# STM32MP153 register map
File version: 1.3
CPU: CM4 r0p1, little endian, no MPU, FPU, 4 interrupt priority bits
Registers are 32-bit, read-write, reset 0x0 unless marked. A register's access mark holds for its fields unless they carry their own. Offsets are from the block's base; [hi:lo] are bit positions.

## ADC_common — Analog-to-Digital Converter
Base 0x48003300
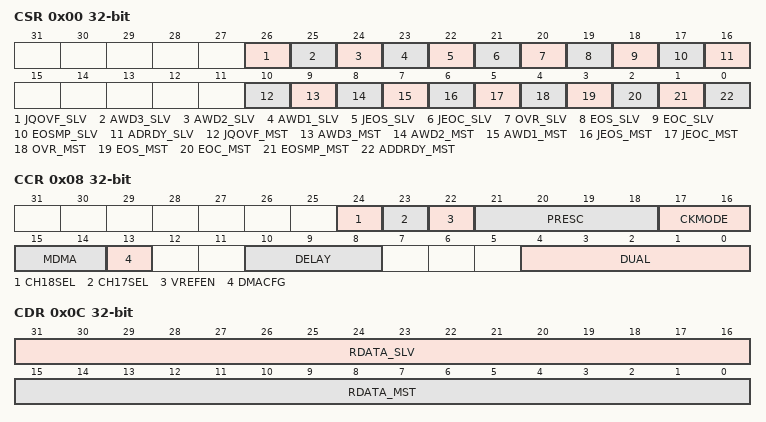
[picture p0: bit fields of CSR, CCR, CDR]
0x00 CSR ro — ADC Common status register
  [26] JQOVF_SLV, [25] AWD3_SLV, [24] AWD2_SLV, [23] AWD1_SLV, [22] JEOS_SLV, [21] JEOC_SLV, [20] OVR_SLV, [19] EOS_SLV, [18] EOC_SLV, [17] EOSMP_SLV, [16] ADRDY_SLV, [10] JQOVF_MST, [9] AWD3_MST, [8] AWD2_MST, [7] AWD1_MST, [6] JEOS_MST, [5] JEOC_MST, [4] OVR_MST, [3] EOS_MST, [2] EOC_MST, [1] EOSMP_MST, [0] ADDRDY_MST
0x08 CCR — ADC common control register
  [24] CH18SEL
  [23] CH17SEL
  [22] VREFEN — VREFINT enable
  [21:18] PRESC — ADC prescaler
  [17:16] CKMODE — ADC clock mode
  [15:14] MDMA
  [13] DMACFG
  [10:8] DELAY
  [4:0] DUAL
0x0C CDR ro — Common regular data register for dual mode
  [31:16] RDATA_SLV, [15:0] RDATA_MST
0x10 CDR2 ro — Common regular data register for dual mode
  [31:0] RDATA_ALT

## CCU
Base 0x44010000
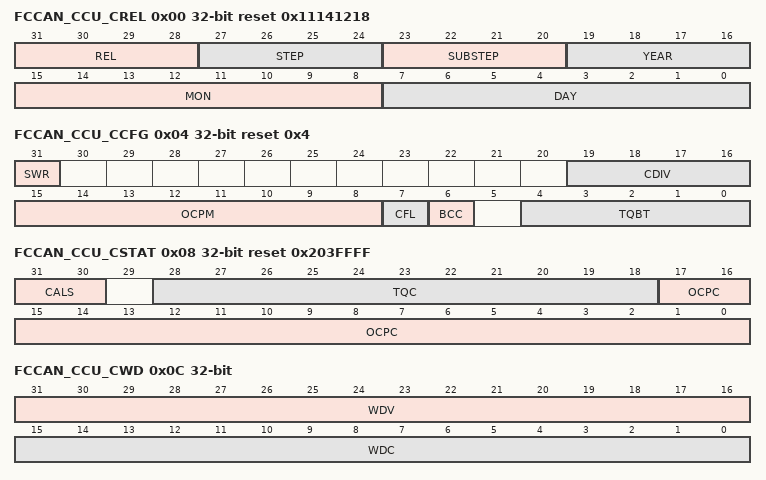
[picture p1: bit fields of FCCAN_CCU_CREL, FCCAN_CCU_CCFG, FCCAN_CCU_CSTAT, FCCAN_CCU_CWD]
0x00 FCCAN_CCU_CREL ro reset 0x11141218 — Clock calibration unit core release register
  [31:28] REL, [27:24] STEP, [23:20] SUBSTEP, [19:16] YEAR, [15:8] MON, [7:0] DAY
0x04 FCCAN_CCU_CCFG reset 0x4 — Calibration configuration register
  [31] SWR, [19:16] CDIV, [15:8] OCPM, [7] CFL, [6] BCC, [4:0] TQBT
0x08 FCCAN_CCU_CSTAT ro reset 0x203FFFF — Calibration status register
  [31:30] CALS, [28:18] TQC, [17:0] OCPC
0x0C FCCAN_CCU_CWD access per field — The calibration watchdog is started after the first falling edge when the calibration FSM is in state Not_Calibrated (CCU_CSTAT.CALS = 00). In this state the calibration watchdog monitors the message received. In case no message was received until the calibration watchdog has counted down to 0, the calibration FSM stays in state Not_Calibrated (CCU_CSTAT.CALS = 00), the counter is reloaded with FDCAN_RWD.WDC and basic calibration is restarted after the next falling edge. When in state Basic_Calibrated (CCU_CSTAT.CALS = 01), the calibration watchdog is restarted with each received message . In case no message was received until the calibration watchdog has counted down to 0, the calibration FSM returns to state Not_Calibrated (CCU_CSTAT.CALS = 00), the counter is reloaded with FDCAN_RWD.WDC and basic calibration is restarted after the next falling edge. When a quartz message is received, state Precision_Calibrated (CCU_CSTAT.CALS = 10) is entered and the calibration watchdog is restarted. In this state the calibration watchdog monitors the quartz message received input. In case no message from a quartz controlled node is received by the attached TTCAN until the calibration watchdog has counted down to 0, the calibration FSM transits back to state Basic_Calibrated (CCU_CSTAT.CALS = 01). The signal is active when the CAN protocol engine on the attached TTCAN is started i.e. when the INIT bit is reset. A calibration watchdog event also sets interrupt flag CCU_IR.CWE. If enabled by CCU_IE.CWEE, interrupt line is activated (set to high). Interrupt line remains active until interrupt flag CCU_IR.CWE is reset.
  [31:16] WDV ro, [15:0] WDC rw
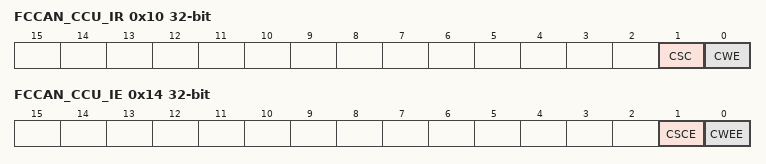
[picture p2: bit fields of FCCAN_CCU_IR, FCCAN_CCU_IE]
0x10 FCCAN_CCU_IR — The flags are set when one of the listed conditions is detected (edge-sensitive). The flags remain set until the Host clears them. A flag is cleared by writing a 1 to the corresponding bit position. Writing a 0 has no effect. A hard reset will clear the register. The configuration of CCU_IE controls whether an interrupt is generated or not.
  [1] CSC, [0] CWE
0x14 FCCAN_CCU_IE — The settings in the CU interrupt enable register determine whether a status change in the CU interrupt register will be signaled on an interrupt line.
  [1] CSCE, [0] CWEE

## CRC1
Base 0x58009000
Same registers: CRC2 0x4C004000
0x00 CRC_DR reset 0xFFFFFFFF — CRC data register
0x04 CRC_IDR — CRC independent data register
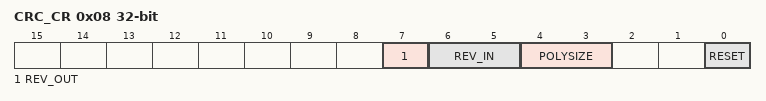
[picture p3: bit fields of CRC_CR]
0x08 CRC_CR — CRC control register
  [7] REV_OUT, [6:5] REV_IN, [4:3] POLYSIZE, [0] RESET
0x10 CRC_INIT reset 0xFFFFFFFF — CRC initial value
0x14 CRC_POL reset 0x4C11DB7 — CRC polynomial
